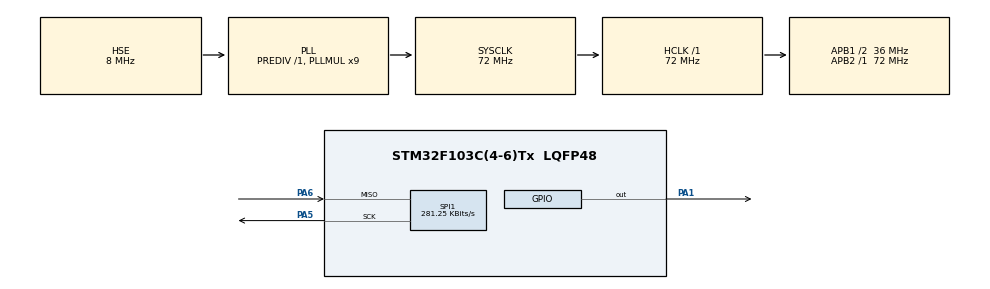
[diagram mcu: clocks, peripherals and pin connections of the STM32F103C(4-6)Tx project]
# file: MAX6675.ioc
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Mcu.Family=STM32F1
Mcu.Name=STM32F103C(4-6)Tx
Mcu.Package=LQFP48
NVIC.PriorityGroup=NVIC_PRIORITYGROUP_4
NVIC.SPI1_IRQn=true\:0\:0\:false\:false\:true
NVIC.TIM3_IRQn=true\:0\:0\:false\:false\:true
PA1.PinState=GPIO_PIN_SET
PA1.Signal=GPIO_Output
PA13.Mode=Serial_Wire
PA13.Signal=SYS_JTMS-SWDIO
PA14.Mode=Serial_Wire
PA14.Signal=SYS_JTCK-SWCLK
PA5.Mode=RX_Only_Simplex_Unidirect_Master
PA5.Signal=SPI1_SCK
PA6.Mode=RX_Only_Simplex_Unidirect_Master
PA6.Signal=SPI1_MISO
PD0-OSC_IN.Mode=HSE-External-Oscillator
PD0-OSC_IN.Signal=RCC_OSC_IN
PD1-OSC_OUT.Mode=HSE-External-Oscillator
PD1-OSC_OUT.Signal=RCC_OSC_OUT
ProjectManager.HeapSize=0x200
ProjectManager.StackSize=0x400
ProjectManager.TargetToolchain=SW4STM32
RCC.ADCPresc=RCC_ADCPCLK2_DIV8
RCC.AHBFreq_Value=72000000
RCC.APB1CLKDivider=RCC_HCLK_DIV2
RCC.APB1Freq_Value=36000000
RCC.APB1TimFreq_Value=72000000
RCC.APB2Freq_Value=72000000
RCC.APB2TimFreq_Value=72000000
RCC.HCLKFreq_Value=72000000
RCC.PLLMUL=RCC_PLL_MUL9
RCC.PLLSourceVirtual=RCC_PLLSOURCE_HSE
RCC.SYSCLKFreq_VALUE=72000000
RCC.SYSCLKSource=RCC_SYSCLKSOURCE_PLLCLK
RCC.USBFreq_Value=72000000
SPI1.BaudRatePrescaler=SPI_BAUDRATEPRESCALER_256
SPI1.CalculateBaudRate=281.25 KBits/s
SPI1.DataSize=SPI_DATASIZE_8BIT
SPI1.Direction=SPI_DIRECTION_2LINES_RXONLY
SPI1.Mode=SPI_MODE_MASTER
SPI1.VirtualType=VM_MASTER
TIM3.ClockDivision=TIM_CLOCKDIVISION_DIV1
TIM3.Period=4096
TIM3.Prescaler=7200
VP_TIM3_VS_ClockSourceINT.Mode=Internal
board=MAX6675

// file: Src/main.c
/**
  ******************************************************************************
  * File Name          : main.c
  * Description        : Main program body
  ******************************************************************************
  ** This notice applies to any and all portions of this file
  * that are not between comment pairs USER CODE BEGIN and
  * USER CODE END. Other portions of this file, whether
  * inserted by the user or by software development tools
  * are owned by their respective copyright owners.
  *
  * COPYRIGHT(c) 2017 STMicroelectronics
  *
  * Redistribution and use in source and binary forms, with or without modification,
  * are permitted provided that the following conditions are met:
  *   1. Redistributions of source code must retain the above copyright notice,
  *      this list of conditions and the following disclaimer.
  *   2. Redistributions in binary form must reproduce the above copyright notice,
  *      this list of conditions and the following disclaimer in the documentation
  *      and/or other materials provided with the distribution.
  *   3. Neither the name of STMicroelectronics nor the names of its contributors
  *      may be used to endorse or promote products derived from this software
  *      without specific prior written permission.
  *
  * THIS SOFTWARE IS PROVIDED BY THE COPYRIGHT HOLDERS AND CONTRIBUTORS "AS IS"
  * AND ANY EXPRESS OR IMPLIED WARRANTIES, INCLUDING, BUT NOT LIMITED TO, THE
  * IMPLIED WARRANTIES OF MERCHANTABILITY AND FITNESS FOR A PARTICULAR PURPOSE ARE
  * DISCLAIMED. IN NO EVENT SHALL THE COPYRIGHT HOLDER OR CONTRIBUTORS BE LIABLE
  * FOR ANY DIRECT, INDIRECT, INCIDENTAL, SPECIAL, EXEMPLARY, OR CONSEQUENTIAL
  * DAMAGES (INCLUDING, BUT NOT LIMITED TO, PROCUREMENT OF SUBSTITUTE GOODS OR
  * SERVICES; LOSS OF USE, DATA, OR PROFITS; OR BUSINESS INTERRUPTION) HOWEVER
  * CAUSED AND ON ANY THEORY OF LIABILITY, WHETHER IN CONTRACT, STRICT LIABILITY,
  * OR TORT (INCLUDING NEGLIGENCE OR OTHERWISE) ARISING IN ANY WAY OUT OF THE USE
  * OF THIS SOFTWARE, EVEN IF ADVISED OF THE POSSIBILITY OF SUCH DAMAGE.
  *
  ******************************************************************************
  */
#include "main.h"
#include "stm32f1xx_hal.h"

SPI_HandleTypeDef hspi1;

TIM_HandleTypeDef htim3;

/* USER CODE BEGIN PV */
/* Private variables ---------------------------------------------------------*/

/* USER CODE END PV */

void SystemClock_Config(void);
static void MX_GPIO_Init(void);
static void MX_TIM3_Init(void);
static void MX_SPI1_Init(void);

/* USER CODE BEGIN PFP */
/* Private function prototypes -----------------------------------------------*/

/* USER CODE END PFP */

/* USER CODE BEGIN 0 */
// hspi 	= pointer to the spi_handle e.g: &hspi1
// cs_port 	= port of the ChipSelect(CS) Pin e.g: GPIOA
// cs_pin	= pin of the ChipSelect(CS) Pin e.g: GPIO_PIN_1 -> CS is connected to PA1
// returns 	= float current temperature in °C; 0.25°C resolution
extern float read_max6675(SPI_HandleTypeDef *hspi, uint8_t cs_port, uint8_t cs_pin)
{
  uint8_t data[2];			//create and initialize data container
  data[0] = 0;
  data[1] = 0;
  uint32_t timeout = 255;	//255ms timeout on spi bus
  uint16_t n_bytes = 2;		//data consists over 2 8-bits(byte)
  uint16_t combined_bit = 0x00;	//combination of both bytes
  HAL_StatusTypeDef status_hal = HAL_ERROR;	//finding out whether spi-bus is working properly (HAL_OK)

  //select chip by pulling cs line down
  HAL_GPIO_WritePin(GPIOA, GPIO_PIN_1, GPIO_PIN_RESET);
  HAL_Delay(1); // timing requirement for chip needed 100ns time before applying clock this is 1ms

  //request data over spi-bus
  status_hal = HAL_SPI_Receive(hspi, data, n_bytes, timeout);

  //deselect chip by pulling cs line up
  HAL_GPIO_WritePin(GPIOA, GPIO_PIN_1, GPIO_PIN_SET);

  //combine msb and lsb to 16-bit
  combined_bit = (data[0] << 8) | data[1];

  //right shift 3 digits
  uint16_t temp_raw = combined_bit >> 3;

  //conversion from µV/°C increments to temp
  temp_raw = temp_raw -1;
  float increment = 0.25;
  float temp = (float) temp_raw * increment;

  return temp;
}

/* USER CODE END 0 */

//----------------------------------------------------
//				WIRING:
//----------------------------------------------------
//	stm32f103c6t8 	<->	max6675
//	(SPI1 SCK)	A5	<->	SCK(Clock)
//	(SPI1 MISO)	A6	<->	SO (MISO)
// 	(GPIO PIN)	A1	<->	CS (ChipSelect)
//----------------------------------------------------
int main(void)
{

  /* MCU Configuration----------------------------------------------------------*/

  /* Reset of all peripherals, Initializes the Flash interface and the Systick. */
  HAL_Init();

  /* Configure the system clock */
  SystemClock_Config();

  /* Initialize all configured peripherals */
  MX_GPIO_Init();
  MX_TIM3_Init();
  MX_SPI1_Init();

  /* USER CODE BEGIN 2 */
  HAL_Delay(500);
  float temp=0;
  /* USER CODE END 2 */

  /* Infinite loop */
  while (1)
  {
		temp = read_max6675(&hspi1, GPIOA, GPIO_PIN_1);
		HAL_Delay(250);
  }

}

/** System Clock Configuration
*/
void SystemClock_Config(void)
{

  RCC_OscInitTypeDef RCC_OscInitStruct;
  RCC_ClkInitTypeDef RCC_ClkInitStruct;

    /**Initializes the CPU, AHB and APB busses clocks
    */
  RCC_OscInitStruct.OscillatorType = RCC_OSCILLATORTYPE_HSE;
  RCC_OscInitStruct.HSEState = RCC_HSE_ON;
  RCC_OscInitStruct.HSEPredivValue = RCC_HSE_PREDIV_DIV1;
  RCC_OscInitStruct.HSIState = RCC_HSI_ON;
  RCC_OscInitStruct.PLL.PLLState = RCC_PLL_ON;
  RCC_OscInitStruct.PLL.PLLSource = RCC_PLLSOURCE_HSE;
  RCC_OscInitStruct.PLL.PLLMUL = RCC_PLL_MUL9;
  if (HAL_RCC_OscConfig(&RCC_OscInitStruct) != HAL_OK)
  {
    _Error_Handler(__FILE__, __LINE__);
  }

    /**Initializes the CPU, AHB and APB busses clocks
    */
  RCC_ClkInitStruct.ClockType = RCC_CLOCKTYPE_HCLK|RCC_CLOCKTYPE_SYSCLK
                              |RCC_CLOCKTYPE_PCLK1|RCC_CLOCKTYPE_PCLK2;
  RCC_ClkInitStruct.SYSCLKSource = RCC_SYSCLKSOURCE_PLLCLK;
  RCC_ClkInitStruct.AHBCLKDivider = RCC_SYSCLK_DIV1;
  RCC_ClkInitStruct.APB1CLKDivider = RCC_HCLK_DIV2;
  RCC_ClkInitStruct.APB2CLKDivider = RCC_HCLK_DIV1;

  if (HAL_RCC_ClockConfig(&RCC_ClkInitStruct, FLASH_LATENCY_2) != HAL_OK)
  {
    _Error_Handler(__FILE__, __LINE__);
  }

    /**Configure the Systick interrupt time
    */
  HAL_SYSTICK_Config(HAL_RCC_GetHCLKFreq()/1000);

    /**Configure the Systick
    */
  HAL_SYSTICK_CLKSourceConfig(SYSTICK_CLKSOURCE_HCLK);

  /* SysTick_IRQn interrupt configuration */
  HAL_NVIC_SetPriority(SysTick_IRQn, 0, 0);
}

/* SPI1 init function */
static void MX_SPI1_Init(void)
{

  hspi1.Instance = SPI1;
  hspi1.Init.Mode = SPI_MODE_MASTER;
  hspi1.Init.Direction = SPI_DIRECTION_2LINES_RXONLY;
  hspi1.Init.DataSize = SPI_DATASIZE_8BIT;
  hspi1.Init.CLKPolarity = SPI_POLARITY_LOW;
  hspi1.Init.CLKPhase = SPI_PHASE_1EDGE;
  hspi1.Init.NSS = SPI_NSS_SOFT;
  hspi1.Init.BaudRatePrescaler = SPI_BAUDRATEPRESCALER_256;
  hspi1.Init.FirstBit = SPI_FIRSTBIT_MSB;
  hspi1.Init.TIMode = SPI_TIMODE_DISABLE;
  hspi1.Init.CRCCalculation = SPI_CRCCALCULATION_DISABLE;
  hspi1.Init.CRCPolynomial = 10;
  if (HAL_SPI_Init(&hspi1) != HAL_OK)
  {
    _Error_Handler(__FILE__, __LINE__);
  }

}

/* TIM3 init function */
static void MX_TIM3_Init(void)
{

  TIM_ClockConfigTypeDef sClockSourceConfig;
  TIM_MasterConfigTypeDef sMasterConfig;

  htim3.Instance = TIM3;
  htim3.Init.Prescaler = 7200;
  htim3.Init.CounterMode = TIM_COUNTERMODE_UP;
  htim3.Init.Period = 4096;
  htim3.Init.ClockDivision = TIM_CLOCKDIVISION_DIV1;
  htim3.Init.AutoReloadPreload = TIM_AUTORELOAD_PRELOAD_DISABLE;
  if (HAL_TIM_Base_Init(&htim3) != HAL_OK)
  {
    _Error_Handler(__FILE__, __LINE__);
  }

  sClockSourceConfig.ClockSource = TIM_CLOCKSOURCE_INTERNAL;
  if (HAL_TIM_ConfigClockSource(&htim3, &sClockSourceConfig) != HAL_OK)
  {
    _Error_Handler(__FILE__, __LINE__);
  }

  sMasterConfig.MasterOutputTrigger = TIM_TRGO_RESET;
  sMasterConfig.MasterSlaveMode = TIM_MASTERSLAVEMODE_DISABLE;
  if (HAL_TIMEx_MasterConfigSynchronization(&htim3, &sMasterConfig) != HAL_OK)
  {
    _Error_Handler(__FILE__, __LINE__);
  }

}

/** Configure pins as
        * Analog
        * Input
        * Output
        * EVENT_OUT
        * EXTI
*/
static void MX_GPIO_Init(void)
{

  GPIO_InitTypeDef GPIO_InitStruct;

  /* GPIO Ports Clock Enable */
  __HAL_RCC_GPIOD_CLK_ENABLE();
  __HAL_RCC_GPIOA_CLK_ENABLE();

  /*Configure GPIO pin Output Level */
  HAL_GPIO_WritePin(GPIOA, GPIO_PIN_1, GPIO_PIN_SET);

  /*Configure GPIO pin : PA1 */
  GPIO_InitStruct.Pin = GPIO_PIN_1;
  GPIO_InitStruct.Mode = GPIO_MODE_OUTPUT_PP;
  GPIO_InitStruct.Speed = GPIO_SPEED_FREQ_LOW;
  HAL_GPIO_Init(GPIOA, &GPIO_InitStruct);

}

void _Error_Handler(char * file, int line)
{
  while(1)
  {
  }
}

/************************ (C) COPYRIGHT STMicroelectronics *****END OF FILE****/
